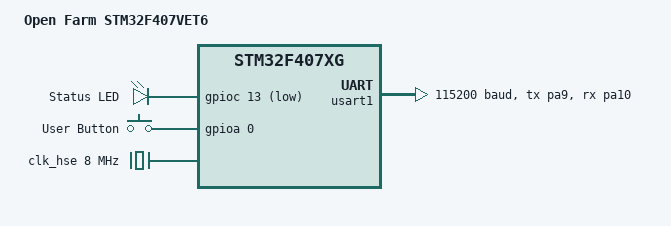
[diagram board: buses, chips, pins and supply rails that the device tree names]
/dts-v1/;
#include <st/f4/stm32f407Xg.dtsi>
#include <st/f4/stm32f407v(e-g)tx-pinctrl.dtsi>

/ {
    model = "Open Farm STM32F407VET6";
    compatible = "open_farm,open-farm-f407vet6";

    chosen {
        zephyr,console = &usart1;
        zephyr,shell-uart = &usart1;
        zephyr,sram = &sram0;
        zephyr,flash = &flash0;
    };

    aliases {
        led0 = &status_led;
        sw0 = &user_button;
    };

    leds {
        compatible = "gpio-leds";

        status_led: status_led {
            gpios = <&gpioc 13 GPIO_ACTIVE_LOW>;
            label = "Status LED";
        };
    };

    buttons {
        compatible = "gpio-keys";

        user_button: user_button {
            gpios = <&gpioa 0 GPIO_ACTIVE_HIGH>;
            label = "User Button";
        };
    };
};

&clk_hse {
    clock-frequency = <8000000>;
    status = "okay";
};

&pll {
    div-m = <8>;
    mul-n = <336>;
    div-p = <2>;
    div-q = <7>;
    clocks = <&clk_hse>;
    status = "okay";
};

&rcc {
    clocks = <&pll>;
    clock-frequency = <168000000>;
    ahb-prescaler = <1>;
    apb1-prescaler = <4>;
    apb2-prescaler = <2>;
};

&usart1 {
    pinctrl-0 = <&usart1_tx_pa9 &usart1_rx_pa10>;
    pinctrl-names = "default";
    current-speed = <115200>;
    status = "okay";
};

&gpioa {
    status = "okay";
};

&gpioc {
    status = "okay";
};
